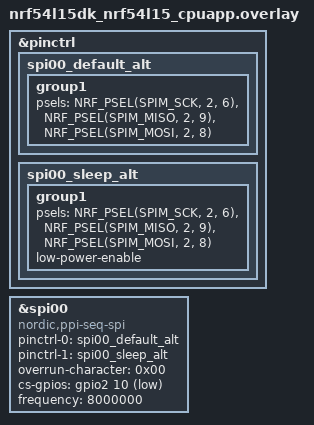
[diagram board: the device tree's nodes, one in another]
/*
 * Copyright (c) 2026 Nordic Semiconductor ASA
 *
 * SPDX-License-Identifier: LicenseRef-Nordic-5-Clause
 */

&pinctrl {
	spi00_default_alt: spi00_default_alt {
		group1 {
			psels = <NRF_PSEL(SPIM_SCK, 2, 6)>,
				<NRF_PSEL(SPIM_MISO, 2, 9)>,
				<NRF_PSEL(SPIM_MOSI, 2, 8)>;
		};
	};

	spi00_sleep_alt: spi00_sleep_alt {
		group1 {
			psels = <NRF_PSEL(SPIM_SCK, 2, 6)>,
				<NRF_PSEL(SPIM_MISO, 2, 9)>,
				<NRF_PSEL(SPIM_MOSI, 2, 8)>;
			low-power-enable;
		};
	};
};

/delete-node/ &mx25r64;

sample_spi: &spi00 {
	compatible = "nordic,ppi-seq-spi";
	status = "okay";
	pinctrl-0 = <&spi00_default_alt>;
	pinctrl-1 = <&spi00_sleep_alt>;
	pinctrl-names = "default", "sleep";
	overrun-character = <0x00>;
	cs-gpios = <&gpio2 10 GPIO_ACTIVE_LOW>;
	frequency = <8000000>;
};
